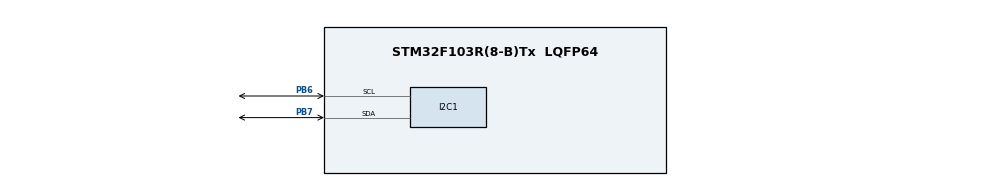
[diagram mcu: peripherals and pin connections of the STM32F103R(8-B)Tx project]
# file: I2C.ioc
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Dma.I2C1_RX.0.Direction=DMA_PERIPH_TO_MEMORY
Dma.I2C1_RX.0.Instance=DMA1_Channel7
Dma.I2C1_RX.0.MemDataAlignment=DMA_MDATAALIGN_BYTE
Dma.I2C1_RX.0.MemInc=DMA_MINC_ENABLE
Dma.I2C1_RX.0.Mode=DMA_NORMAL
Dma.I2C1_RX.0.PeriphDataAlignment=DMA_PDATAALIGN_BYTE
Dma.I2C1_RX.0.PeriphInc=DMA_PINC_DISABLE
Dma.I2C1_RX.0.Priority=DMA_PRIORITY_LOW
Dma.I2C1_TX.1.Direction=DMA_MEMORY_TO_PERIPH
Dma.I2C1_TX.1.Instance=DMA1_Channel6
Dma.I2C1_TX.1.MemDataAlignment=DMA_MDATAALIGN_BYTE
Dma.I2C1_TX.1.MemInc=DMA_MINC_ENABLE
Dma.I2C1_TX.1.Mode=DMA_NORMAL
Dma.I2C1_TX.1.PeriphDataAlignment=DMA_PDATAALIGN_BYTE
Dma.I2C1_TX.1.PeriphInc=DMA_PINC_DISABLE
Dma.I2C1_TX.1.Priority=DMA_PRIORITY_LOW
Dma.Request0=I2C1_RX
Dma.Request1=I2C1_TX
I2C1.I2C_Mode=I2C_Fast
Mcu.Family=STM32F1
Mcu.Name=STM32F103R(8-B)Tx
Mcu.Package=LQFP64
NVIC.DMA1_Channel6_IRQn=true\:0\:0\:false\:false\:true\:false
NVIC.DMA1_Channel7_IRQn=true\:0\:0\:false\:false\:true\:false
NVIC.PriorityGroup=NVIC_PRIORITYGROUP_4
PB6.Mode=I2C
PB6.Signal=I2C1_SCL
PB7.Mode=I2C
PB7.Signal=I2C1_SDA
PD0-OSC_IN.Mode=HSE-External-Oscillator
PD0-OSC_IN.Signal=RCC_OSC_IN
PD1-OSC_OUT.Mode=HSE-External-Oscillator
PD1-OSC_OUT.Signal=RCC_OSC_OUT
ProjectManager.HeapSize=0x200
ProjectManager.StackSize=0x400
ProjectManager.TargetToolchain=MDK-ARM V5
RCC.APB1Freq_Value=8000000
RCC.APB2Freq_Value=8000000
RCC.PLLSourceVirtual=RCC_PLLSOURCE_HSE
RCC.USBFreq_Value=16000000
VP_SYS_VS_ND.Mode=No_Debug
board=I2C

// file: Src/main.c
/**
  ******************************************************************************
  * @file           : main.c
  * @brief          : Main program body
  ******************************************************************************
  ** This notice applies to any and all portions of this file
  * that are not between comment pairs USER CODE BEGIN and
  * USER CODE END. Other portions of this file, whether
  * inserted by the user or by software development tools
  * are owned by their respective copyright owners.
  *
  * COPYRIGHT(c) 2020 STMicroelectronics
  *
  * Redistribution and use in source and binary forms, with or without modification,
  * are permitted provided that the following conditions are met:
  *   1. Redistributions of source code must retain the above copyright notice,
  *      this list of conditions and the following disclaimer.
  *   2. Redistributions in binary form must reproduce the above copyright notice,
  *      this list of conditions and the following disclaimer in the documentation
  *      and/or other materials provided with the distribution.
  *   3. Neither the name of STMicroelectronics nor the names of its contributors
  *      may be used to endorse or promote products derived from this software
  *      without specific prior written permission.
  *
  * THIS SOFTWARE IS PROVIDED BY THE COPYRIGHT HOLDERS AND CONTRIBUTORS "AS IS"
  * AND ANY EXPRESS OR IMPLIED WARRANTIES, INCLUDING, BUT NOT LIMITED TO, THE
  * IMPLIED WARRANTIES OF MERCHANTABILITY AND FITNESS FOR A PARTICULAR PURPOSE ARE
  * DISCLAIMED. IN NO EVENT SHALL THE COPYRIGHT HOLDER OR CONTRIBUTORS BE LIABLE
  * FOR ANY DIRECT, INDIRECT, INCIDENTAL, SPECIAL, EXEMPLARY, OR CONSEQUENTIAL
  * DAMAGES (INCLUDING, BUT NOT LIMITED TO, PROCUREMENT OF SUBSTITUTE GOODS OR
  * SERVICES; LOSS OF USE, DATA, OR PROFITS; OR BUSINESS INTERRUPTION) HOWEVER
  * CAUSED AND ON ANY THEORY OF LIABILITY, WHETHER IN CONTRACT, STRICT LIABILITY,
  * OR TORT (INCLUDING NEGLIGENCE OR OTHERWISE) ARISING IN ANY WAY OUT OF THE USE
  * OF THIS SOFTWARE, EVEN IF ADVISED OF THE POSSIBILITY OF SUCH DAMAGE.
  *
  ******************************************************************************
  */
#include "main.h"
#include "stm32f1xx_hal.h"

I2C_HandleTypeDef hi2c1;
DMA_HandleTypeDef hdma_i2c1_rx;
DMA_HandleTypeDef hdma_i2c1_tx;

/* USER CODE BEGIN PV */
/* Private variables ---------------------------------------------------------*/

/* USER CODE END PV */

void SystemClock_Config(void);
static void MX_GPIO_Init(void);
static void MX_DMA_Init(void);
static void MX_I2C1_Init(void);

/* USER CODE BEGIN PFP */
/* Private function prototypes -----------------------------------------------*/

/* USER CODE END PFP */

/* USER CODE BEGIN 0 */
int at24_HAL_WriteBytes(I2C_HandleTypeDef *hi2c,uint16_t DevAdress,uint16_t MemAddress,uint8_t *pData,uint16_t TxBufferSize)
{
	if(MemAddress+TxBufferSize>16)
	{
		while(
				HAL_I2C_Mem_Write(hi2c,(uint16_t)DevAdress, (uint16_t)MemAddress,I2C_MEMADD_SIZE_8BIT, pData, (uint16_t)16-MemAddress,1000)!=HAL_OK
			);
		*pData=*pData + (16-MemAddress);
		while(
				HAL_I2C_Mem_Write(hi2c,(uint16_t)DevAdress, (uint16_t)16, I2C_MEMADD_SIZE_8BIT, pData, (uint16_t)((MemAddress+TxBufferSize)-16),1000)!=HAL_OK
			);
	}
	else
	{
		while((TxBufferSize-16)>0)
		{
			while(
				HAL_I2C_Mem_Write(hi2c,(uint16_t)DevAdress, (uint16_t)MemAddress,I2C_MEMADD_SIZE_8BIT, pData, (uint16_t)16,1000) !=  HAL_OK
					);
			TxBufferSize-=16;
			pData+=16;
			MemAddress+=16;
		}
			while(
				HAL_I2C_Mem_Write(hi2c,(uint16_t)DevAdress, (uint16_t)MemAddress,I2C_MEMADD_SIZE_8BIT, pData, (uint16_t)TxBufferSize,1000)!=HAL_OK
					);
	}
	return 1;
}

int at24_HAL_ReadBytes(I2C_HandleTypeDef *hi2c,uint16_t DevAdress,uint16_t MemAddress,uint8_t *pData,uint16_t RxBufferSize)
{
	int TimeOut;
	while((RxBufferSize-16)>0)
	{
		TimeOut=0;
		while(HAL_I2C_Mem_Write(hi2c,(uint16_t)DevAdress, (uint16_t)MemAddress,I2C_MEMADD_SIZE_8BIT, pData, (uint16_t)16,1000) != HAL_OK && TimeOut < 10)
		{
			TimeOut++;
		}
		RxBufferSize-=16;
		pData+=16;
		MemAddress+=16;
	}
	TimeOut=0;
	while(HAL_I2C_Mem_Write(hi2c,(uint16_t)DevAdress, (uint16_t)MemAddress, I2C_MEMADD_SIZE_8BIT, pData, (uint16_t)RxBufferSize,1000) != HAL_OK && TimeOut < 10)
	{
		TimeOut++;
	}
	return 1;
}
/* USER CODE END 0 */

int main(void)
{

  /* MCU Configuration----------------------------------------------------------*/

  /* Reset of all peripherals, Initializes the Flash interface and the Systick. */
  HAL_Init();

  /* Configure the system clock */
  SystemClock_Config();

  /* Initialize all configured peripherals */
  MX_GPIO_Init();
  MX_DMA_Init();
  MX_I2C1_Init();
  /* USER CODE BEGIN 2 */
 uint8_t d[1]={0x05};
 uint8_t c[1];

 printf("write 1 byte data %d on address 0 of AT25C02\r\n",d[0]);
 at24_HAL_WriteBytes(&hi2c1, 0xA0, 0, d, 1);
 HAL_Delay(10);
 at24_HAL_ReadBytes(&hi2c1, 0xA0, 0, c, 1);
 printf("read 1 byte data %d on address 0 of AT25C02\r\n",c[0]);

  /* USER CODE END 2 */

  /* Infinite loop */
  while (1)
  {

  }

}

void SystemClock_Config(void)
{

  RCC_OscInitTypeDef RCC_OscInitStruct;
  RCC_ClkInitTypeDef RCC_ClkInitStruct;

    /**Initializes the CPU, AHB and APB busses clocks
    */
  RCC_OscInitStruct.OscillatorType = RCC_OSCILLATORTYPE_HSI;
  RCC_OscInitStruct.HSIState = RCC_HSI_ON;
  RCC_OscInitStruct.HSICalibrationValue = 16;
  RCC_OscInitStruct.PLL.PLLState = RCC_PLL_NONE;
  if (HAL_RCC_OscConfig(&RCC_OscInitStruct) != HAL_OK)
  {
    _Error_Handler(__FILE__, __LINE__);
  }

    /**Initializes the CPU, AHB and APB busses clocks
    */
  RCC_ClkInitStruct.ClockType = RCC_CLOCKTYPE_HCLK|RCC_CLOCKTYPE_SYSCLK
                              |RCC_CLOCKTYPE_PCLK1|RCC_CLOCKTYPE_PCLK2;
  RCC_ClkInitStruct.SYSCLKSource = RCC_SYSCLKSOURCE_HSI;
  RCC_ClkInitStruct.AHBCLKDivider = RCC_SYSCLK_DIV1;
  RCC_ClkInitStruct.APB1CLKDivider = RCC_HCLK_DIV1;
  RCC_ClkInitStruct.APB2CLKDivider = RCC_HCLK_DIV1;

  if (HAL_RCC_ClockConfig(&RCC_ClkInitStruct, FLASH_LATENCY_0) != HAL_OK)
  {
    _Error_Handler(__FILE__, __LINE__);
  }

    /**Configure the Systick interrupt time
    */
  HAL_SYSTICK_Config(HAL_RCC_GetHCLKFreq()/1000);

    /**Configure the Systick
    */
  HAL_SYSTICK_CLKSourceConfig(SYSTICK_CLKSOURCE_HCLK);

  /* SysTick_IRQn interrupt configuration */
  HAL_NVIC_SetPriority(SysTick_IRQn, 0, 0);
}

/* I2C1 init function */
static void MX_I2C1_Init(void)
{

  hi2c1.Instance = I2C1;
  hi2c1.Init.ClockSpeed = 400000;
  hi2c1.Init.DutyCycle = I2C_DUTYCYCLE_2;
  hi2c1.Init.OwnAddress1 = 0;
  hi2c1.Init.AddressingMode = I2C_ADDRESSINGMODE_7BIT;
  hi2c1.Init.DualAddressMode = I2C_DUALADDRESS_DISABLE;
  hi2c1.Init.OwnAddress2 = 0;
  hi2c1.Init.GeneralCallMode = I2C_GENERALCALL_DISABLE;
  hi2c1.Init.NoStretchMode = I2C_NOSTRETCH_DISABLE;
  if (HAL_I2C_Init(&hi2c1) != HAL_OK)
  {
    _Error_Handler(__FILE__, __LINE__);
  }

}

static void MX_DMA_Init(void)
{
  /* DMA controller clock enable */
  __HAL_RCC_DMA1_CLK_ENABLE();

  /* DMA interrupt init */
  /* DMA1_Channel6_IRQn interrupt configuration */
  HAL_NVIC_SetPriority(DMA1_Channel6_IRQn, 0, 0);
  HAL_NVIC_EnableIRQ(DMA1_Channel6_IRQn);
  /* DMA1_Channel7_IRQn interrupt configuration */
  HAL_NVIC_SetPriority(DMA1_Channel7_IRQn, 0, 0);
  HAL_NVIC_EnableIRQ(DMA1_Channel7_IRQn);

}

/** Configure pins as
        * Analog
        * Input
        * Output
        * EVENT_OUT
        * EXTI
*/
static void MX_GPIO_Init(void)
{

  /* GPIO Ports Clock Enable */
  __HAL_RCC_GPIOD_CLK_ENABLE();
  __HAL_RCC_GPIOB_CLK_ENABLE();

}

void _Error_Handler(char *file, int line)
{
  while(1)
  {
  }
}

/************************ (C) COPYRIGHT STMicroelectronics *****END OF FILE****/
